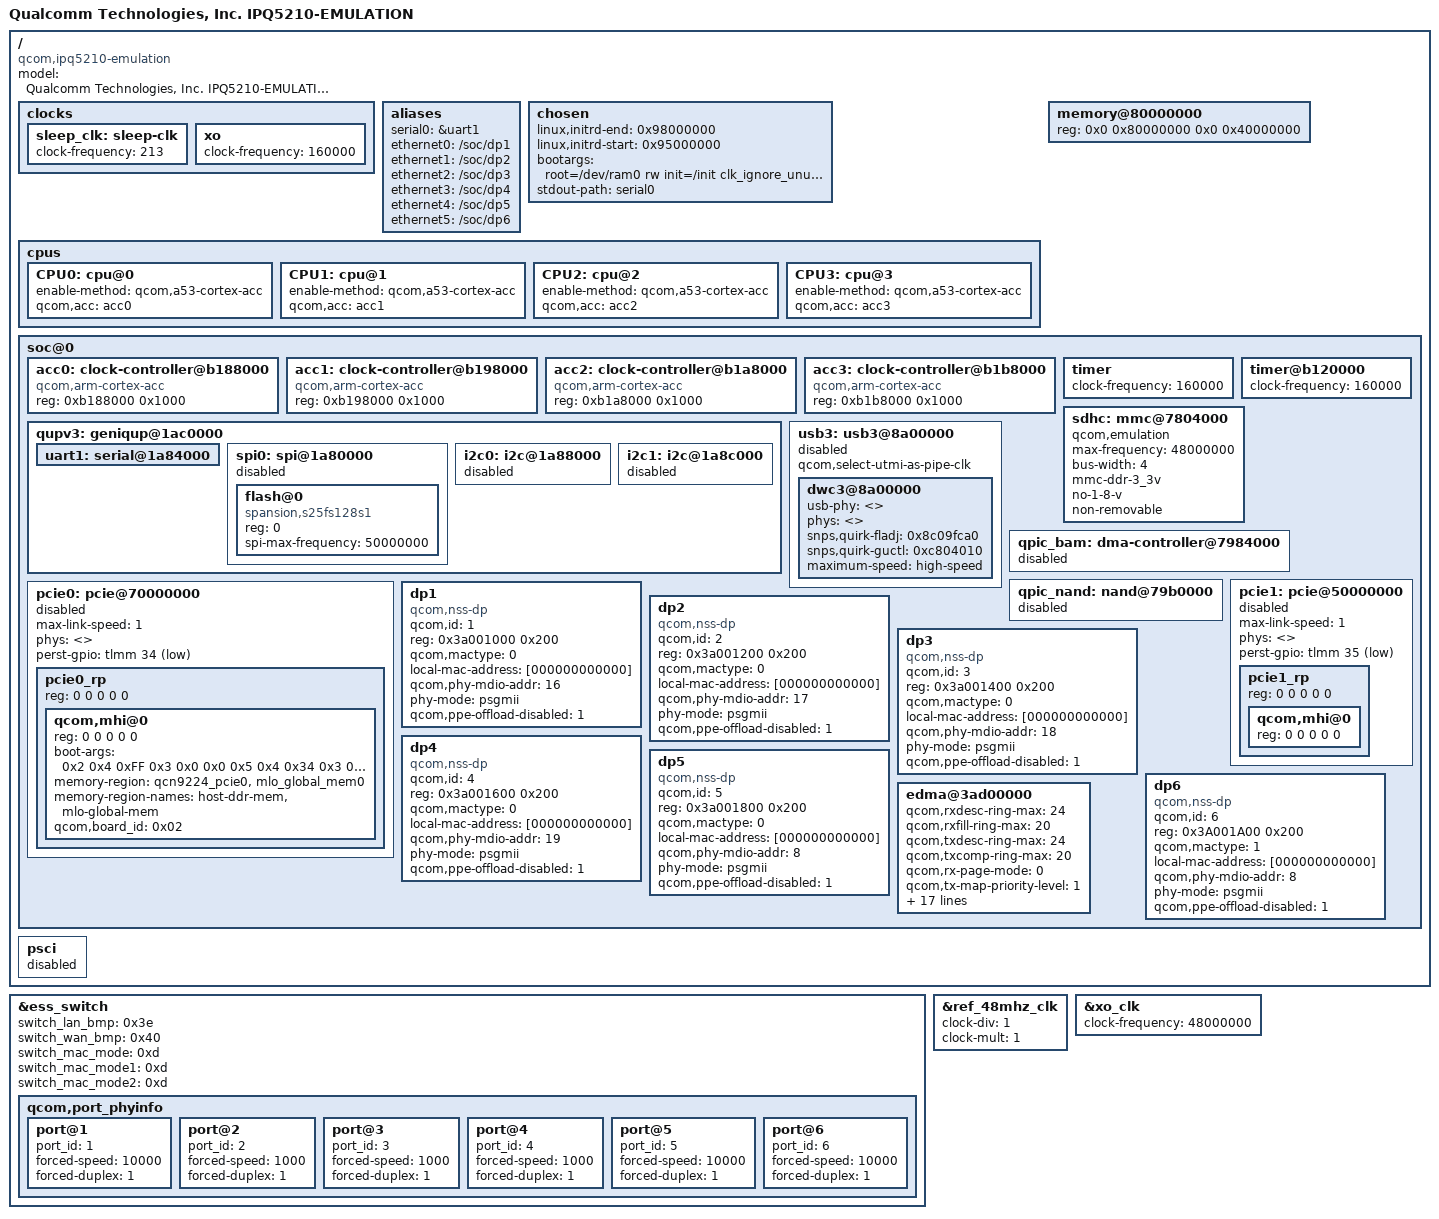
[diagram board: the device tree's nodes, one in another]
// SPDX-License-Identifier: (GPL-2.0+ OR BSD-3-Clause)
/*
 * IPQ5210 Emulation board device tree source
 *
 * Copyright (c) 2020-2021 The Linux Foundation. All rights reserved.
 * Copyright (c) 2022-2025 Qualcomm Innovation Center, Inc. All rights reserved.
 */

/dts-v1/;

#include "ipq5210.dtsi"
#include "ipq5210-default-memory.dtsi"

/ {
	model = "Qualcomm Technologies, Inc. IPQ5210-EMULATION";
	compatible = "qcom,ipq5210-emulation", "qcom,ipq5210";

	/delete-node/ firmware;
	/delete-node/ ctx-save;

	/* Timer freq for rumi = timer freq / 150 */
	clocks {
		sleep_clk: sleep-clk {
			clock-frequency = <213>;
		};

		xo: xo {
			clock-frequency = <160000>;
		};
	};

	aliases {
		serial0 = &uart1;
		ethernet0 = "/soc/dp1";
		ethernet1 = "/soc/dp2";
		ethernet2 = "/soc/dp3";
		ethernet3 = "/soc/dp4";
		ethernet4 = "/soc/dp5";
		ethernet5 = "/soc/dp6";
	};

	chosen {
		linux,initrd-end = <0x98000000>;
		linux,initrd-start = <0x95000000>;
		bootargs = "root=/dev/ram0 rw init=/init clk_ignore_unused earlycon";
		stdout-path = "serial0";
	};

	cpus: cpus {
		CPU0: cpu@0 {
			enable-method = "qcom,a53-cortex-acc";
			qcom,acc = <&acc0>;
		};

		CPU1: cpu@1 {
			enable-method = "qcom,a53-cortex-acc";
			qcom,acc = <&acc1>;
		};

		CPU2: cpu@2 {
			enable-method = "qcom,a53-cortex-acc";
			qcom,acc = <&acc2>;
		};

		CPU3: cpu@3 {
			enable-method = "qcom,a53-cortex-acc";
			qcom,acc = <&acc3>;
		};
	};

	memory@80000000 {
		reg = <0x0 0x80000000 0x0 0x40000000>;
	};

	soc@0 {
		acc0: clock-controller@b188000 {
			compatible = "qcom,arm-cortex-acc";
			reg = <0xb188000 0x1000>;
		};

		acc1: clock-controller@b198000 {
			compatible = "qcom,arm-cortex-acc";
			reg = <0xb198000 0x1000>;
		};

		acc2:clock-controller@b1a8000 {
			compatible = "qcom,arm-cortex-acc";
			reg = <0xb1a8000 0x1000>;
		};

		acc3:clock-controller@b1b8000 {
			compatible = "qcom,arm-cortex-acc";
			reg = <0xb1b8000 0x1000>;
		};

		/* Timer freq for rumi = timer freq / 150 */
		timer {
			clock-frequency = <160000>;
		};

		timer@b120000 {
			clock-frequency = <160000>;
		};

		qupv3: geniqup@1ac0000 {
			status = "okay";

			uart1: serial@1a84000 {
				status = "okay";
			};

			spi0: spi@1a80000 {
				status = "disabled";

				flash@0 {
					compatible = "spansion,s25fs128s1", "jedec,spi-nor";
					#address-cells = <1>;
					#size-cells = <1>;
					reg = <0>;
					spi-max-frequency = <50000000>;
				};
			};

			i2c0: i2c@1a88000 {
				status = "disabled";
			};

			i2c1: i2c@1a8c000 {
				status = "disabled";
			};
		};

		sdhc: mmc@7804000 {
			qcom,emulation;
			/* over-ride the frequency to 48Mhz for emulation platform */
			max-frequency = <48000000>;
			bus-width = <4>;
			/* Force 3.3V, because only that will support on emulation platform */
			mmc-ddr-3_3v;
			/* quirk to disable SDR104, SDR50 modes */
			no-1-8-v;
			non-removable;
			status = "okay";
		};

		usb3: usb3@8a00000 {
			qcom,select-utmi-as-pipe-clk;
			status = "disabled";

			dwc3@8a00000 {
				usb-phy = <>;
				phys = <>;
				phy-names = "";
				snps,quirk-fladj = <0x8c09fca0>;
				snps,quirk-guctl = <0xc804010>;
				maximum-speed = "high-speed";
			};
		};

		qpic_bam: dma-controller@7984000 {
			status="disabled";
		};

		qpic_nand: nand@79b0000 {
			status="disabled";
		};

		pcie0: pcie@70000000 {
			max-link-speed = <1>;
			phys = <>;
			phy-names = "";
			perst-gpio = <&tlmm 34 GPIO_ACTIVE_LOW>;
			status = "disabled";

			pcie0_rp {
				reg = <0 0 0 0 0>;
				qcom,mhi@0 {
					reg = <0 0 0 0 0>;
					boot-args = <0x2 0x4 0xFF 0x3 0x0 0x0  /* MX Rail, Invalid GPIO, Drive strength 0x3 */
							0x5 0x4 0x34 0x3 0x0 0x16 /* CX Rail, GPIO52, Drive strength 0x3, CPR1_fuse 0x0, CPR0_fuse 0x16 */
							0x0 0x4 0x0 0x0 0x0 0x0>; /* End of arguments */
					memory-region = <&qcn9224_pcie0>, <&mlo_global_mem0>;
					memory-region-names = "host-ddr-mem", "mlo-global-mem";
					qcom,board_id = <0x02>;
				};
			};
		};

		pcie1: pcie@50000000 {
			max-link-speed = <1>;
			phys = <>;
			phy-names = "";
			perst-gpio = <&tlmm 35 GPIO_ACTIVE_LOW>;
			status = "disabled";

			pcie1_rp {
				reg = <0 0 0 0 0>;
				qcom,mhi@0 {
					reg = <0 0 0 0 0>;
				};
			};
		};

		dp1 {
			device_type = "network";
			compatible = "qcom,nss-dp";
			qcom,id = <1>;
			reg = <0x3a001000 0x200>;
			qcom,mactype = <0>;
			local-mac-address = [000000000000];
			qcom,phy-mdio-addr = <16>;
			phy-mode = "psgmii";
			qcom,ppe-offload-disabled = <1>;
		};

		dp2 {
			device_type = "network";
			compatible = "qcom,nss-dp";
			qcom,id = <2>;
			reg = <0x3a001200 0x200>;
			qcom,mactype = <0>;
			local-mac-address = [000000000000];
			qcom,phy-mdio-addr = <17>;
			phy-mode = "psgmii";
			qcom,ppe-offload-disabled = <1>;
		};


		dp3 {
			device_type = "network";
			compatible = "qcom,nss-dp";
			qcom,id = <3>;
			reg = <0x3a001400 0x200>;
			qcom,mactype = <0>;
			local-mac-address = [000000000000];
			qcom,phy-mdio-addr = <18>;
			phy-mode = "psgmii";
			qcom,ppe-offload-disabled = <1>;
		};

		dp4 {
			device_type = "network";
			compatible = "qcom,nss-dp";
			qcom,id = <4>;
			reg = <0x3a001600 0x200>;
			qcom,mactype = <0>;
			local-mac-address = [000000000000];
			qcom,phy-mdio-addr = <19>;
			phy-mode = "psgmii";
			qcom,ppe-offload-disabled = <1>;
		};

		dp5 {
			device_type = "network";
			compatible = "qcom,nss-dp";
			qcom,id = <5>;
			reg = <0x3a001800 0x200>;
			qcom,mactype = <0>;
			local-mac-address = [000000000000];
			qcom,phy-mdio-addr = <8>;
			phy-mode = "psgmii";
			qcom,ppe-offload-disabled = <1>;
		};

		dp6 {
			device_type = "network";
			compatible = "qcom,nss-dp";
			qcom,id = <6>;
			reg = <0x3A001A00 0x200>;
			qcom,mactype = <1>;
			local-mac-address = [000000000000];
			qcom,phy-mdio-addr = <8>;
			phy-mode = "psgmii";
			qcom,ppe-offload-disabled = <1>;
		};

		/* EDMA host driver configuration */
		edma@3ad00000 {
			qcom,rxdesc-ring-max = <24>;
			qcom,rxfill-ring-max = <20>;
			qcom,txdesc-ring-max = <24>;
			qcom,txcomp-ring-max = <20>;
			qcom,rx-page-mode = <0>;
			qcom,tx-map-priority-level = <1>;
			qcom,rx-map-priority-level = <1>;
			qcom,txdesc-fc-grp-map = <1 2 3 4 5 6>;
			qcom,vp-id = <8>;
			interrupts = <0 332 4>, <0 333 4>, <0 334 4>, <0 335 4>,
				   <0 336 4>, <0 337 4>, <0 338 4>, <0 339 4>,
				   <0 340 4>, <0 341 4>, <0 342 4>, <0 343 4>,
				   <0 344 4>, <0 345 4>, <0 346 4>, <0 347 4>,
				   <0 348 4>, <0 349 4>, <0 350 4>, <0 351 4>, /* TX Complete ring IRQ info (0 - 19) */

				   <0 288 4>, <0 289 4>, <0 290 4>, <0 291 4>,
				   <0 292 4>, <0 293 4>, <0 294 4>, <0 295 4>,
				   <0 296 4>, <0 297 4>, <0 298 4>, <0 299 4>,
				   <0 300 4>, <0 301 4>, <0 302 4>, <0 303 4>,
				   <0 304 4>, <0 305 4>, <0 306 4>, <0 307 4>,
				   <0 308 4>, <0 309 4>, <0 310 4>, <0 311 4>, /* RX desc ring IRQ info (0 - 23) */

				   <0 312 4>, <0 313 4>, <0 314 4>, <0 315 4>,
				   <0 316 4>, <0 317 4>, <0 318 4>, <0 319 4>,
				   <0 320 4>, <0 321 4>, <0 322 4>, <0 323 4>,
				   <0 324 4>, <0 325 4>, <0 326 4>, <0 327 4>,
				   <0 328 4>, <0 329 4>, <0 330 4>, <0 331 4>, /* RX fill ring IRQ info (0 - 19) */

				   <0 352 4>;					/* Misc interrupt */
			interrupt-names = "txcmpl_0", "txcmpl_1", "txcmpl_2", "txcmpl_3",
				   "txcmpl_4", "txcmpl_5", "txcmpl_6", "txcmpl_7",
				   "txcmpl_8", "txcmpl_9", "txcmpl_10", "txcmpl_11",
				   "txcmpl_12", "txcmpl_13", "txcmpl_14", "txcmpl_15",
				   "txcmpl_16", "txcmpl_17", "txcmpl_18", "txcmpl_19",

				   "rxdesc_0", "rxdesc_1", "rxdesc_2", "rxdesc_3",
				   "rxdesc_4", "rxdesc_5", "rxdesc_6", "rxdesc_7",
				   "rxdesc_8", "rxdesc_9", "rxdesc_10", "rxdesc_11",
				   "rxdesc_12", "rxdesc_13", "rxdesc_14", "rxdesc_15",
				   "rxdesc_16", "rxdesc_17", "rxdesc_18", "rxdesc_19",
				   "rxdesc_20", "rxdesc_21", "rxdesc_22", "rxdesc_23",

				   "rxfill_0", "rxfill_1", "rxfill_2", "rxfill_3",
				   "rxfill_4", "rxfill_5", "rxfill_6", "rxfill_7",
				   "rxfill_8", "rxfill_9", "rxfill_10", "rxfill_11",
				   "rxfill_12", "rxfill_13", "rxfill_14", "rxfill_15",
				   "rxfill_16", "rxfill_17", "rxfill_18", "rxfill_19",

				   "misc_err";
		};
	};

	psci {
		status = "disabled";
	};
};

&ess_switch {
	switch_lan_bmp = <0x3e>; /* lan port bitmap */
	switch_wan_bmp = <0x40>; /* wan port bitmap */
	switch_mac_mode = <0xd>; /* mac mode for uniphy instance0*/
	switch_mac_mode1 = <0xd>; /* mac mode for uniphy instance1*/
	switch_mac_mode2 = <0xd>; /* mac mode for uniphy instance2*/

	qcom,port_phyinfo {
		port@1 {
			port_id = <1>;
			forced-speed = <10000>;
			forced-duplex = <1>;
		};
		port@2 {
			port_id = <2>;
			forced-speed = <1000>;
			forced-duplex = <1>;
		};
		port@3 {
			port_id = <3>;
			forced-speed = <1000>;
			forced-duplex = <1>;
		};
		port@4 {
			port_id = <4>;
			forced-speed = <1000>;
			forced-duplex = <1>;
		};
		port@5 {
			port_id = <5>;
			forced-speed = <10000>;
			forced-duplex = <1>;
		};
		port@6 {
			port_id = <6>;
			forced-speed = <10000>;
			forced-duplex = <1>;
		};
	};
};

&ref_48mhz_clk {
	clock-div = <1>;
	clock-mult = <1>;
};

&xo_clk {
	clock-frequency = <48000000>;
};
